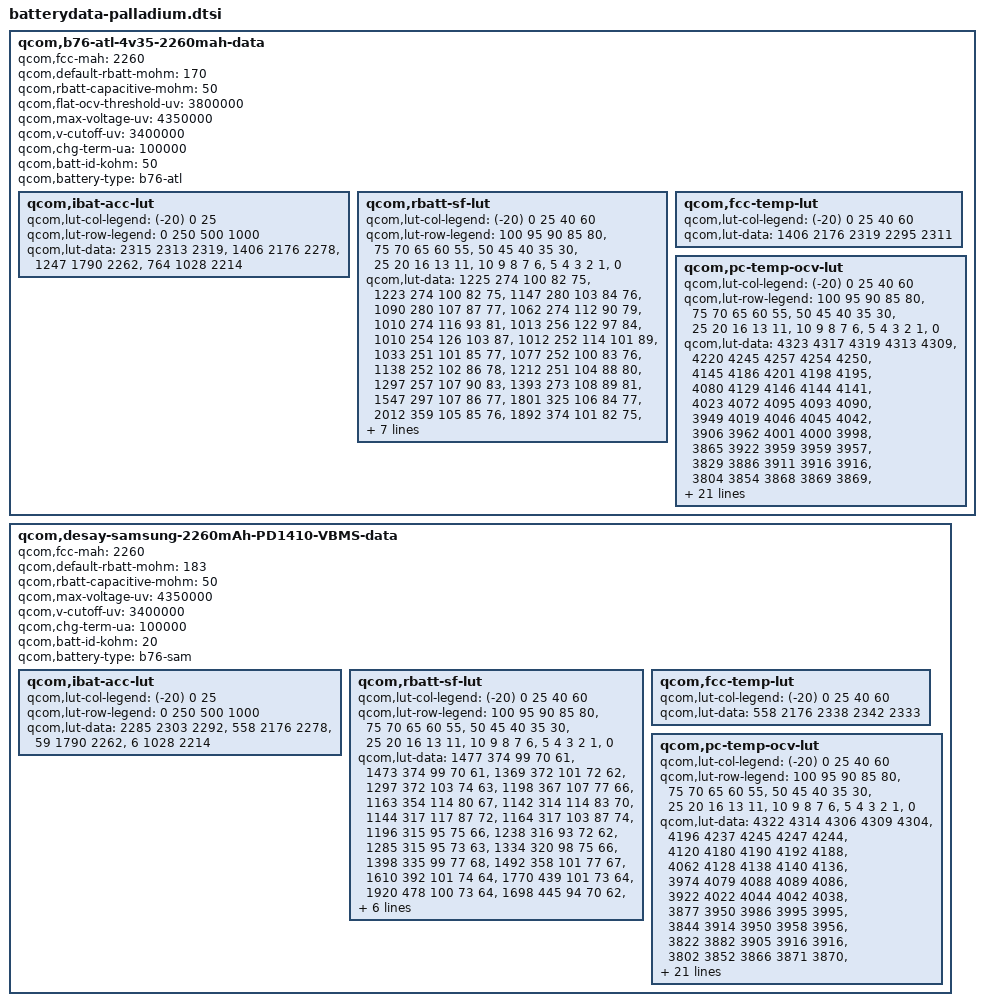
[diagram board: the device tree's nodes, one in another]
/* Copyright (c) 2013-2014, The Linux Foundation. All rights reserved.
 *
 * This program is free software; you can redistribute it and/or modify
 * it under the terms of the GNU General Public License version 2 and
 * only version 2 as published by the Free Software Foundation.
 *
 * This program is distributed in the hope that it will be useful,
 * but WITHOUT ANY WARRANTY; without even the implied warranty of
 * MERCHANTABILITY or FITNESS FOR A PARTICULAR PURPOSE.  See the
 * GNU General Public License for more details.
 */

qcom,b76-atl-4v35-2260mah-data {
	qcom,fcc-mah = <2260>;
	qcom,default-rbatt-mohm = <170>;
	qcom,rbatt-capacitive-mohm = <50>;
	qcom,flat-ocv-threshold-uv = <3800000>;
	qcom,max-voltage-uv = <4350000>;
	qcom,v-cutoff-uv = <3400000>;
	qcom,chg-term-ua = <100000>;
	qcom,batt-id-kohm = <50>;
	qcom,battery-type = "b76-atl";

	qcom,ibat-acc-lut {
		qcom,lut-col-legend = <(-20) 0 25>;
		qcom,lut-row-legend = <0 250 500 1000>;
		qcom,lut-data = <2315 2313 2319>,
		<1406 2176 2278>,
		<1247 1790 2262>,
		<764 1028 2214>;
	};
	qcom,rbatt-sf-lut {
		qcom,lut-col-legend = <(-20) 0 25 40 60>;
		qcom,lut-row-legend = <100 95 90 85 80>,
				<75 70 65 60 55>,
				<50 45 40 35 30>,
				<25 20 16 13 11>,
				<10 9 8 7 6>,
				<5 4 3 2 1>,
				<0>;
		qcom,lut-data = <1225 274 100 82 75>,
				<1223 274 100 82 75>,
				<1147 280 103 84 76>,
				<1090 280 107 87 77>,
				<1062 274 112 90 79>,
				<1010 274 116 93 81>,
				<1013 256 122 97 84>,
				<1010 254 126 103 87>,
				<1012 252 114 101 89>,
				<1033 251 101 85 77>,
				<1077 252 100 83 76>,
				<1138 252 102 86 78>,
				<1212 251 104 88 80>,
				<1297 257 107 90 83>,
				<1393 273 108 89 81>,
				<1547 297 107 86 77>,
				<1801 325 106 84 77>,
				<2012 359 105 85 76>,
				<1892 374 101 82 75>,
				<1868 381 101 83 76>,
				<2024 397 103 84 77>,
				<2207 416 106 86 79>,
				<2430 440 110 89 80>,
				<2710 468 115 92 82>,
				<3054 501 118 92 82>,
				<3496 532 116 90 78>,
				<4098 573 114 88 79>,
				<4946 632 118 91 82>,
				<6331 726 125 97 86>,
				<11499 1408 145 117 111>,
				<11499 1408 145 117 111>;
	};
	qcom,fcc-temp-lut {
		qcom,lut-col-legend = <(-20) 0 25 40 60>;
		qcom,lut-data = <1406 2176 2319 2295 2311>;//<2315 2313 2319 2295 2311>;
	};

	qcom,pc-temp-ocv-lut {
		qcom,lut-col-legend = <(-20) 0 25 40 60>;
		qcom,lut-row-legend = <100 95 90 85 80>,
				<75 70 65 60 55>,
				<50 45 40 35 30>,
				<25 20 16 13 11>,
				<10 9 8 7 6>,
				<5 4 3 2 1>,
				<0>;
		qcom,lut-data =					
		    <4323 4317 4319 4313 4309>,
				<4220 4245 4257 4254 4250>,
				<4145 4186 4201 4198 4195>,
				<4080 4129 4146 4144 4141>,
				<4023 4072 4095 4093 4090>,
				<3949 4019 4046 4045 4042>,
				<3906 3962 4001 4000 3998>,
				<3865 3922 3959 3959 3957>,
				<3829 3886 3911 3916 3916>,
				<3804 3854 3868 3869 3869>,
				<3788 3826 3839 3840 3839>,
				<3775 3803 3816 3817 3816>,
				<3762 3783 3797 3797 3796>,
				<3747 3768 3781 3781 3779>,
				<3732 3757 3767 3764 3759>,
				<3715 3743 3753 3746 3734>,
				<3694 3723 3734 3725 3712>,
				<3674 3706 3712 3702 3689>,
				<3660 3694 3689 3681 3669>,			
				<3647 3680 3683 3676 3664>,
				<3639 3672 3681 3674 3663>,
				<3628 3662 3679 3673 3661>,
				<3617 3658 3677 3671 3659>,
				<3602 3656 3674 3667 3655>,
				<3584 3655 3667 3658 3644>,
				<3561 3652 3646 3634 3613>,
				<3530 3649 3604 3589 3566>,
				<3485 3645 3545 3528 3505>,
				<3414 3544 3466 3447 3422>,
				<3284 3390 3347 3322 3287>,
				<3000 3300 3000 3000 3000>;
	};
};
qcom,desay-samsung-2260mAh-PD1410-VBMS-data {
	qcom,fcc-mah = <2260>;
	qcom,default-rbatt-mohm = <183>;
	qcom,rbatt-capacitive-mohm = <50>;
	qcom,max-voltage-uv = <4350000>;
	qcom,v-cutoff-uv = <3400000>;
	qcom,chg-term-ua = <100000>;
	qcom,batt-id-kohm = <20>;
	qcom,battery-type = "b76-sam";
	qcom,ibat-acc-lut {
		qcom,lut-col-legend = <(-20) 0 25>;
		qcom,lut-row-legend = <0 250 500 1000>;
		qcom,lut-data = <2285 2303 2292>,
		<558 2176 2278>,
		<59 1790 2262>,
		<6 1028 2214>;
	};

	qcom,rbatt-sf-lut {
		qcom,lut-col-legend = <(-20) 0 25 40 60>;
		qcom,lut-row-legend = <100 95 90 85 80>,
				<75 70 65 60 55>,
				<50 45 40 35 30>,
				<25 20 16 13 11>,
				<10 9 8 7 6>,
				<5 4 3 2 1>,
				<0>;
		qcom,lut-data = <1477 374 99 70 61>,
				<1473 374 99 70 61>,
				<1369 372 101 72 62>,
				<1297 372 103 74 63>,
				<1198 367 107 77 66>,
				<1163 354 114 80 67>,
				<1142 314 114 83 70>,
				<1144 317 117 87 72>,
				<1164 317 103 87 74>,
				<1196 315 95 75 66>,
				<1238 316 93 72 62>,
				<1285 315 95 73 63>,
				<1334 320 98 75 66>,
				<1398 335 99 77 68>,
				<1492 358 101 77 67>,
				<1610 392 101 74 64>,
				<1770 439 101 73 64>,
				<1920 478 100 73 64>,
				<1698 445 94 70 62>,
				<1804 465 96 72 63>,
				<1932 476 98 73 64>,
				<2077 489 101 75 66>,
				<2243 505 104 76 67>,
				<2445 522 108 78 69>,
				<2697 538 111 80 70>,
				<3014 557 109 77 64>,
				<3434 579 107 75 64>,
				<4072 613 111 78 67>,
				<5206 661 121 84 74>,
				<9341 924 221 115 107>,
                <9341 924 221 115 107>;/*<149378 96449 73164 55665 58178>;*/
	};

	qcom,fcc-temp-lut {
		qcom,lut-col-legend = <(-20) 0 25 40 60>;
		qcom,lut-data = <558 2176 2338 2342 2333>;//<2334 2340 2338 2342 2333>;
	};
	qcom,pc-temp-ocv-lut {
		qcom,lut-col-legend = <(-20) 0 25 40 60>;
		qcom,lut-row-legend = <100 95 90 85 80>,
				<75 70 65 60 55>,
				<50 45 40 35 30>,
				<25 20 16 13 11>,
				<10 9 8 7 6>,
				<5 4 3 2 1>,
				<0>;
		qcom,lut-data = <4322 4314 4306 4309 4304>,
				<4196 4237 4245 4247 4244>,
				<4120 4180 4190 4192 4188>,
				<4062 4128 4138 4140 4136>,
				<3974 4079 4088 4089 4086>,
				<3922 4022 4044 4042 4038>,
				<3877 3950 3986 3995 3995>,
				<3844 3914 3950 3958 3956>,
				<3822 3882 3905 3916 3916>,
				<3802 3852 3866 3871 3870>,
				<3784 3824 3838 3840 3839>,
				<3766 3798 3816 3818 3816>,
				<3749 3776 3798 3798 3798>,
				<3732 3758 3782 3782 3782>,
				<3716 3742 3768 3768 3762>,
				<3698 3730 3754 3750 3738>,
				<3678 3720 3736 3731 3718>,
				<3658 3711 3714 3708 3694>,
				<3640 3702 3692 3685 3673>,
				<3625 3695 3688 3681 3670>,
				<3614 3690 3686 3680 3669>,
				<3604 3684 3686 3680 3668>,
				<3590 3678 3684 3678 3666>,
				<3576 3670 3680 3675 3664>,
				<3557 3656 3672 3667 3655>,
				<3534 3633 3648 3642 3623>,
				<3503 3597 3601 3596 3574>,
				<3462 3543 3537 3534 3513>,
				<3396 3461 3448 3449 3430>,
				<3280 3322 3316 3320 3302>,
				<3000 3000 3000 3000 3000>;
	};
};
